# CY8C4245AXI_483 register map
File version: 0.1
PSoC 4200
Registers are 32-bit, read-write, no defined reset value unless marked. A register's access mark holds for its fields unless they carry their own. Offsets are from the block's base; lines under a group give offsets from that group; [hi:lo] are bit positions; {n}, {i} and the like mark numbered series; 'fields as' and 'values as' point back to an identical list; <NAME> marks a mode.

## Memory map
0x00000000 CoolerStatusReg
0x00000000 Opamp_REF — OpAmp
0x00000000 Opamp
0x00000000 IDAC_Low — IDAC
0x00000000 IDAC_High — IDAC
0x00000000 Display_I2C — Serial Communication Block
0x00000000 UART — Serial Communication Block
0x00000000 ADC — Sequencing SAR ADC

## CoolerStatusReg
Base 0x00000000
0x400F0061 CoolerStatusReg_STATUS_REG 8-bit
0x400F0081 CoolerStatusReg_MASK_REG 8-bit
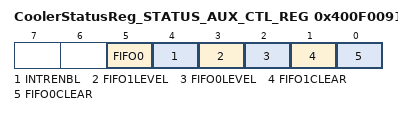
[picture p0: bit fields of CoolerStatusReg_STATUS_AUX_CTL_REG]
0x400F0091 CoolerStatusReg_STATUS_AUX_CTL_REG 8-bit
  [5] FIFO0 — FIFO0 clear
    1=ENABLED (Enable counter); 0=DISABLED (Disable counter)
  [4] INTRENBL — Enables or disables the Interrupt
    1=ENABLED (Interrupt enabled); 0=DISABLED (Interrupt disabled)
  [3] FIFO1LEVEL — FIFO level
    1=ENABLED (FIFO LVL: input mode: FIFO at least 1/2 empty; output mode: FIFO at least 1/2 full); 0=DISABLED (FIFO LVL: input mode: FIFO not full; output mode: FIFO not empty)
  [2] FIFO0LEVEL — FIFO level
    values as FIFO1LEVEL
  [1] FIFO1CLEAR — FIFO clear
    1=ENABLED (Clear FIFO state); 0=DISABLED (Normal FIFO operation)
  [0] FIFO0CLEAR — FIFO clear
    values as FIFO1CLEAR

## Opamp_REF — OpAmp
Base 0x00000000
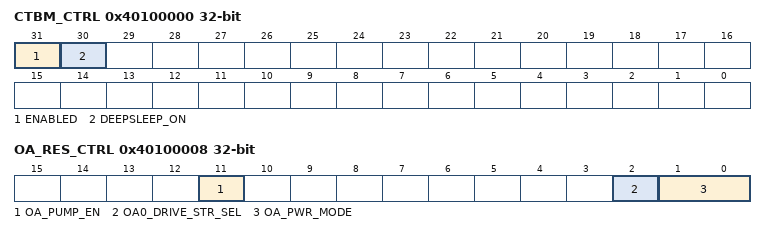
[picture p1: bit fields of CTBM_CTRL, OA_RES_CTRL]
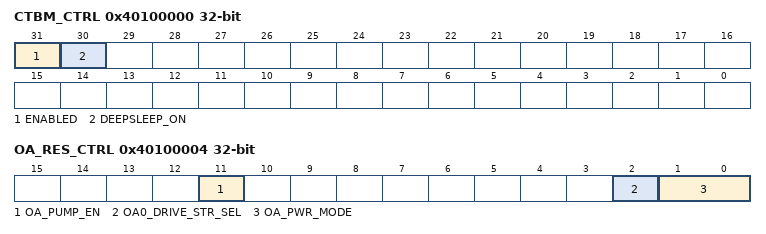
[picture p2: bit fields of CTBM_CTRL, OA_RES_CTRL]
0x40100000 CTBM_CTRL — Global CTB IP and power control
  [31] ENABLED — Selects component behavior in DeepSleep power mode
    0=DISABLE (CTB IP disabled (put analog in power down, open all switches)); 1=ENABLE (CTB IP enabledCTB IP enabled)
  [30] DEEPSLEEP_ON — Selects component behavior in DeepSleep power mode
    0=DISABLE (CTB IP disabled off during DeepSleep power mode); 1=ENABLE (CTB IP remains enabled during DeepSleep power mode (if ENABLED=1))
0x40100008 OA_RES_CTRL — Opamp and resistor control
  [11] OA_PUMP_EN — Selects pump
    0=DISABLE (Pump disabled); 1=ENABLE (Pump enabled)
  [2] OA0_DRIVE_STR_SEL — Opamp output strenght select
    0=Cy1x (Internal only); 1=Cy10x (Output to pin)
  [1:0] OA_PWR_MODE — Selects power for opamp
    0=OFF; 1=LOW (Low power); 2=MED (Medium power); 3=HIGH (High power)
0x40100F14 OA_COMP_TRIM — Opamp Compenation Capacitor Trim
  [1:0] OA_COMP_TRIM
    1=HIGH_SPEED; 2=BALANCED; 3=HIGH_STABILITY

## Opamp
Base 0x00000000
0x40100000 CTBM_CTRL — Global CTB IP and power control
  [31] ENABLED — Selects component behavior in DeepSleep power mode
    0=DISABLE (CTB IP disabled (put analog in power down, open all switches)); 1=ENABLE (CTB IP enabledCTB IP enabled)
  [30] DEEPSLEEP_ON — Selects component behavior in DeepSleep power mode
    0=DISABLE (CTB IP disabled off during DeepSleep power mode); 1=ENABLE (CTB IP remains enabled during DeepSleep power mode (if ENABLED=1))
0x40100004 OA_RES_CTRL — Opamp and resistor control
  [11] OA_PUMP_EN — Selects pump
    0=DISABLE (Pump disabled); 1=ENABLE (Pump enabled)
  [2] OA0_DRIVE_STR_SEL — Opamp output strenght select
    0=Cy1x (Internal only); 1=Cy10x (Output to pin)
  [1:0] OA_PWR_MODE — Selects power for opamp
    0=OFF; 1=LOW (Low power); 2=MED (Medium power); 3=HIGH (High power)
0x40100F08 OA_COMP_TRIM — Opamp Compenation Capacitor Trim
  [1:0] OA_COMP_TRIM
    1=HIGH_SPEED; 2=BALANCED; 3=HIGH_STABILITY

## IDAC_Low — IDAC
Base 0x00000000
Same registers: IDAC_High 0x00000000
0x40080004 CSD_IDAC_POLARITY
0x40080008 CSD_IDAC
0x4008FF00 CSD_TRIM1 — CSD IDAC TRIM1
0x4008FF04 CSD_TRIM2 — CSD IDAC TRIM2
